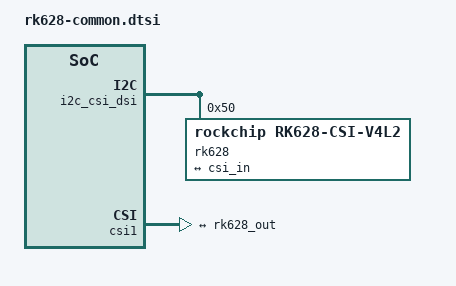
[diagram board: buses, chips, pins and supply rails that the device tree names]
// SPDX-License-Identifier: GPL-2.0

/ {
	i2c_frag: fragment@0 {
		target = <&i2c_csi_dsi>;
		__overlay__ {
			#address-cells = <1>;
			#size-cells = <0>;
			status = "okay";

			rk628: hdmi-bridge@50 {
				compatible = "rockchip,rk628-csi-v4l2";
				reg = <0x50>;
				status = "okay";
				pinctrl-names = "default";
				pinctrl-0 = <&rk628_irq_pins>;
				interrupts = <17 4>; // GPIO17, level high, J8205 pin6
				continues-clk;
				rockchip,camera-module-index = <0>;
				rockchip,camera-module-facing = "back";
				rockchip,camera-module-name = "Radxa-RK628H";
				rockchip,camera-module-lens-name = "HDMI";

				port {
					rk628_out: endpoint {
						remote-endpoint = <&csi_in>;
						clock-lanes = <0>;
					};
				};
			};
		};
	};

	csi_frag: fragment@1 {
		target = <&csi1>;
		__overlay__ {
			status = "okay";
			label = "rk628-capture";	// for udev rules
			port {
				csi_in: endpoint {
					remote-endpoint = <&rk628_out>;
					clock-lanes = <0>;
				};
			};
		};
	};

	fragment@4 {
		target = <&rk628>;
		__dormant__ {
			i2s-enable-default;
		};
	};

	fragment@5 {
		target = <&i2s_clk_consumer>;
		__dormant__ {
			status = "okay";
		};
	};

	fragment@6 {
		target-path = "/";
		__dormant__ {
			rk628_audio: rk628-audio-codec {
				compatible = "linux,spdif-dir";
				#sound-dai-cells = <0>;
				status = "okay";
			};
		};
	};

	fragment@7 {
		target = <&sound>;
		__dormant__ {
			compatible = "simple-audio-card";
			status = "okay";
			simple-audio-card,name = "RK628HDMI";
			simple-audio-card,format = "i2s";
			simple-audio-card,bitclock-master = <&rk628_audio_master>;
			simple-audio-card,frame-master = <&rk628_audio_master>;

			simple-audio-card,cpu {
				sound-dai = <&i2s_clk_consumer>;
				dai-tdm-slot-num = <2>;
				dai-tdm-slot-width = <32>;
			};

			rk628_audio_master: simple-audio-card,codec {
				sound-dai = <&rk628_audio>;
			};
		};
	};

	__overrides__ {
		audio = <0>, "+4+5+6+7";
	};
};
